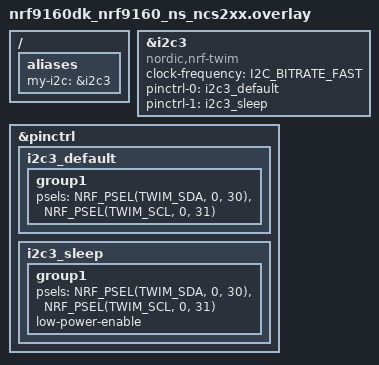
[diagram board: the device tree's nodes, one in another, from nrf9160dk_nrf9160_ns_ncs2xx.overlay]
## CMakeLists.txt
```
#
# Copyright (c) 2018 Nordic Semiconductor
#
# SPDX-License-Identifier: LicenseRef-BSD-5-Clause-Nordic
#

cmake_minimum_required(VERSION 3.13.1)

find_package(Zephyr REQUIRED HINTS $ENV{ZEPHYR_BASE})
project(i2c_scanner)

# NORDIC SDK APP START
target_sources(app PRIVATE src/main.c)
# NORDIC SDK APP END
```

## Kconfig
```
#
# Copyright (c) 2020 Nordic Semiconductor ASA
#
# SPDX-License-Identifier: LicenseRef-Nordic-5-Clause
#

menu "I2C Scanner settings"
config I2C_SCAN_ADDR_START
	int "First address to start scanning I2C devices."
	default 8

config I2C_SCAN_ADDR_STOP
	int "Last address for scanning I2C devices."
	default 127
endmenu

module = I2CScanner
module-str = I2C Scanner Demo Application
source "${ZEPHYR_BASE}/subsys/logging/Kconfig.template.log_config"

menu "Zephyr Kernel"
source "Kconfig.zephyr"
endmenu
```

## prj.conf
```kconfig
#
# Copyright (c) 2019 Nordic Semiconductor ASA
#
# SPDX-License-Identifier: LicenseRef-BSD-5-Clause-Nordic
#
# General config
CONFIG_ASSERT=y
CONFIG_NEWLIB_LIBC=y

#I2C
CONFIG_I2C=y
CONFIG_I2C_NRFX=y

#CONFIG_LOG=y
#CONFIG_I2C_LOG_LEVEL_DBG=y
#CONFIG_LOG_BACKEND_UART=y
#CONFIG_I2C_INIT_PRIORITY=60

# enable console
CONFIG_CONSOLE=y
CONFIG_UART_CONSOLE=y

# Enable RTT
#CONFIG_USE_SEGGER_RTT=n 
#CONFIG_RTT_CONSOLE=n 

# Stacks and heaps
CONFIG_MAIN_STACK_SIZE=2048
CONFIG_HEAP_MEM_POOL_SIZE=8192

# Application Specific settings
CONFIG_I2C_SCAN_ADDR_START=8
CONFIG_I2C_SCAN_ADDR_STOP=127
```

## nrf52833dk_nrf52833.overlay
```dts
&arduino_i2c {
	clock-frequency = <I2C_BITRATE_STANDARD>; 
};
```

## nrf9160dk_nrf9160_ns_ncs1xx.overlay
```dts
/ {
	aliases {
		my-i2c = &i2c3;
	};
};

&i2c3 {
	status = "okay";
	compatible = "nordic,nrf-twim";
	sda-pin = <30>;
	scl-pin = <31>;
	clock-frequency = <I2C_BITRATE_FAST>; 
};
```

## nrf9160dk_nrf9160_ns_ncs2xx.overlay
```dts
/ {
	aliases {
		my-i2c = &i2c3;
	};
};

&i2c3 {
	status = "okay";
	compatible = "nordic,nrf-twim";
	clock-frequency = <I2C_BITRATE_FAST>; 
	pinctrl-0 = <&i2c3_default>;
	pinctrl-1 = <&i2c3_sleep>;
	pinctrl-names = "default", "sleep";	
};

&pinctrl {
	i2c3_default: i2c3_default {
		group1 {
				psels = <NRF_PSEL(TWIM_SDA, 0, 30)>,
						<NRF_PSEL(TWIM_SCL, 0, 31)>;
		};
	};

	i2c3_sleep: i2c3_sleep {
		group1 {
				psels = <NRF_PSEL(TWIM_SDA, 0, 30)>,
						<NRF_PSEL(TWIM_SCL, 0, 31)>;
				low-power-enable;
		};
	};	
};
```

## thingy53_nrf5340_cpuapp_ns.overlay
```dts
/ {
	aliases {
		my-i2c = &i2c1;
	};
};
```

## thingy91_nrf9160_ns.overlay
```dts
/ {
	aliases {
		my-i2c = &i2c2;
	};
};
```

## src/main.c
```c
/*																								*/
/* Copyright (c) 2020 Nordic Semiconductor ASA													*/
/*																								*/
/* SPDX-License-Identifier: LicenseRef-Nordic-5-Clause											*/
#include <zephyr.h>
#include <sys/printk.h>
#include <drivers/i2c.h>

/* Check if devicetree node identifier with the alias "my-i2c" is defined						*/
/* If not defined use the default defined node for the arduino_i2c pins on the development kit 	*/
#if DT_NODE_HAS_STATUS(DT_ALIAS(my_i2c), okay)
	#define I2C_NODE DT_ALIAS(my_i2c)
	#define I2C_DEV	DT_LABEL(I2C_NODE)
#else
	#define I2C_NODE DT_NODELABEL(arduino_i2c)
	#if DT_NODE_HAS_STATUS(I2C_NODE, okay)
		#define I2C_DEV	DT_LABEL(I2C_NODE)
	#else
		#error "Arduino_i2c not defined, specify the I2C bus to use with the alias "my-i2c""
		#define I2C_DEV ""
	#endif
#endif

void main(void)
{
	const struct device *i2c_dev;

	k_sleep(K_SECONDS(1));
	printk("*** I2C scanner started.                    ***\nBoard name      : %s\n", CONFIG_BOARD);

	i2c_dev = device_get_binding(I2C_DEV);
		if (!i2c_dev) {
		printk("I2C: Device driver not found.\n");
		return;
	}

	printk("I2C Port        : %s \n",I2C_DEV);
	printk("Clock Frequency : %d \n",DT_PROP(I2C_NODE, clock_frequency));

#ifndef CONFIG_PINCTRL_NRF
	// From NCS2.0.0 pin-control is used, not possible to read out the used pins from I2C_NODE 
	printk("SDA-PIN         : %d \n",DT_PROP(I2C_NODE, sda_pin));
	printk("SCL-PIN         : %d \n",DT_PROP(I2C_NODE, scl_pin));
#endif

	printk("\n    | 0x00 0x01 0x02 0x03 0x04 0x05 0x06 0x07 0x08 0x09 0x0a 0x0b 0x0c 0x0d 0x0e 0x0f |\n");
	printk(  "----|---------------------------------------------------------------------------------");
	
	uint8_t error = 0u;
	uint8_t dst;
	uint8_t i2c_dev_cnt = 0;
	struct i2c_msg msgs[1];
	msgs[0].buf = &dst;
	msgs[0].len = 1U;
	msgs[0].flags = I2C_MSG_WRITE | I2C_MSG_STOP;

	/* Use the full range of I2C address for display purpose */	
	for (uint16_t x = 0; x <= 0x7f; x++) {
		/* New line every 0x10 address */
		if (x % 0x10 == 0) {
			printk("|\n0x%02x| ",x);	
		}
		/* Range the test with the start and stop value configured in the kconfig */
		if (x >= CONFIG_I2C_SCAN_ADDR_START && x <= CONFIG_I2C_SCAN_ADDR_STOP)	{	
			/* Send the address to read from */
			error = i2c_transfer(i2c_dev, &msgs[0], 1, x);
				/* I2C device found on current address */
				if (error == 0) {
					printk("0x%02x ",x);
					i2c_dev_cnt++;
				}
				else {
					printk(" --  ");
				}
		} else {
			/* Scan value out of range, not scanned */
			printk("     ");
		}
	}
	printk("|\n");
	printk("\nI2C device(s) found on the bus: %d\nScanning done.\n\n", i2c_dev_cnt);
	printk("Find the registered I2C address on: https://i2cdevices.org/addresses\n\n");
}
```
